# AT32F413xx register map
Vendor: Keil; Series: AT32F413; File version: 1.0
CPU: CM4 r0p1, little endian, no MPU, FPU, 4 interrupt priority bits
Registers are 32-bit, read-write, reset 0x0 unless marked. A register's access mark holds for its fields unless they carry their own. Offsets are from the block's base; [hi:lo] are bit positions; {n}, {i} and the like mark numbered series.

## PWR — Power control
Base 0x40007000
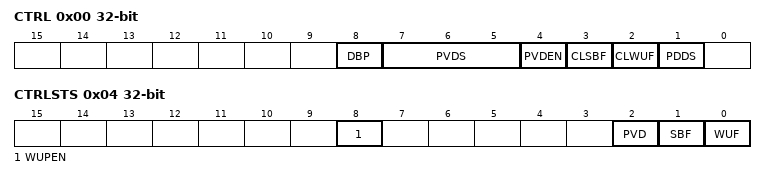
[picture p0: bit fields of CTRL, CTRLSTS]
0x00 CTRL — Power control register (PWR_CTRL)
  [8] DBP — Disable Backup Domain write protection
  [7:5] PVDS — PVD Level Selection
  [4] PVDEN — Power Voltage Detector Enable
  [3] CLSBF — Clear STANDBY Flag
  [2] CLWUF — Clear Wake-up Flag
  [1] PDDS — Power Down Deep Sleep
0x04 CTRLSTS — Power control register (PWR_CTRLST)
  [8] WUPEN — Enable WKUP pin
  [2] PVD ro — PVD Output
  [1] SBF ro — STANDBY Flag
  [0] WUF ro — Wake-Up Flag

## GPIOA — General purpose I/O
Base 0x40010800
Same registers: GPIOB 0x40010C00, GPIOC 0x40011000, GPIOD 0x40011400, GPIOF 0x40011C00
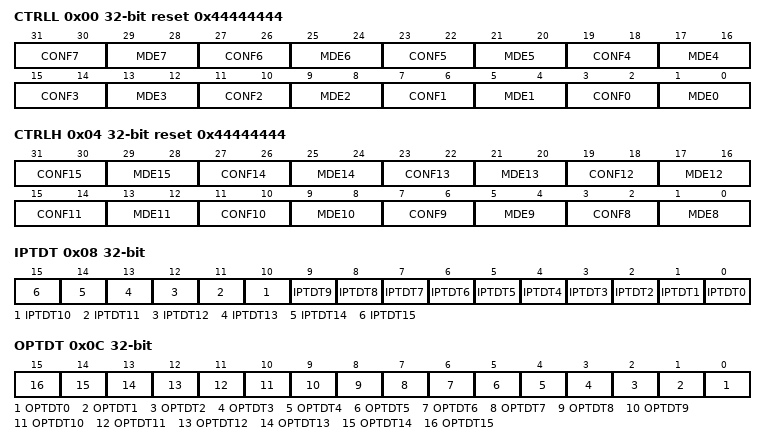
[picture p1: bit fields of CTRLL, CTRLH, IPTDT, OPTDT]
0x00 CTRLL reset 0x44444444 — Port configuration register low (GPIOn_CTRLL)
  [31:30] CONF7 — Port n.7 configuration bits
  [29:28] MDE7 — Port n.7 mode bits
  [27:26] CONF6 — Port n.6 configuration bits
  [25:24] MDE6 — Port n.6 mode bits
  [23:22] CONF5 — Port n.5 configuration bits
  [21:20] MDE5 — Port n.5 mode bits
  [19:18] CONF4 — Port n.4 configuration bits
  [17:16] MDE4 — Port n.4 mode bits
  [15:14] CONF3 — Port n.3 configuration bits
  [13:12] MDE3 — Port n.3 mode bits
  [11:10] CONF2 — Port n.2 configuration bits
  [9:8] MDE2 — Port n.2 mode bits
  [7:6] CONF1 — Port n.1 configuration bits
  [5:4] MDE1 — Port n.1 mode bits
  [3:2] CONF0 — Port n.0 configuration bits
  [1:0] MDE0 — Port n.0 mode bits
0x04 CTRLH reset 0x44444444 — Port configuration register high (GPIOn_CTRLH)
  [31:30] CONF15 — Port n.15 configuration bits
  [29:28] MDE15 — Port n.15 mode bits
  [27:26] CONF14 — Port n.14 configuration bits
  [25:24] MDE14 — Port n.14 mode bits
  [23:22] CONF13 — Port n.13 configuration bits
  [21:20] MDE13 — Port n.13 mode bits
  [19:18] CONF12 — Port n.12 configuration bits
  [17:16] MDE12 — Port n.12 mode bits
  [15:14] CONF11 — Port n.11 configuration bits
  [13:12] MDE11 — Port n.11 mode bits
  [11:10] CONF10 — Port n.10 configuration bits
  [9:8] MDE10 — Port n.10 mode bits
  [7:6] CONF9 — Port n.9 configuration bits
  [5:4] MDE9 — Port n.9 mode bits
  [3:2] CONF8 — Port n.8 configuration bits
  [1:0] MDE8 — Port n.8 mode bits
0x08 IPTDT ro — Port input data register (GPIOn_IPTDT)
  [n] IPTDT{n} (n=0..15) — Port input data
0x0C OPTDT — Port output data register (GPIOn_OPTDT)
  [n] OPTDT{n} (n=0..15) — Port output data
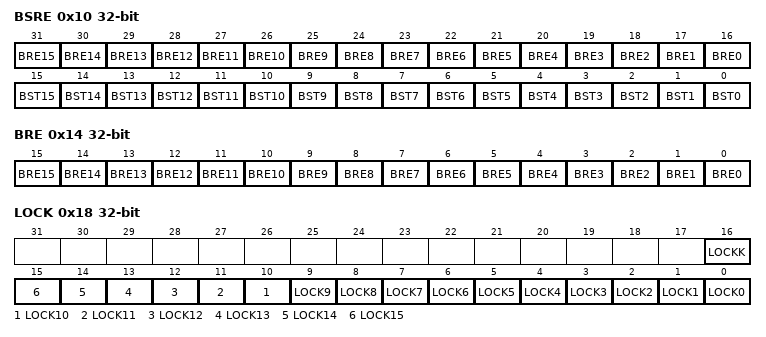
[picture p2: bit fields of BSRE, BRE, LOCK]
0x10 BSRE — Port bit set/reset register (GPIOn_BSRE)
  [n+16] BRE{n} (n=0..15) — Reset bit {n}
  [n] BST{n} (n=3..15) — Set bit {n}
  [2] BST2 — Set bit 1
  [1] BST1 — Set bit 1
  [0] BST0 — Set bit 0
0x14 BRE — Port bit reset register (GPIOn_BRE)
  [n] BRE{n} (n=3..15) — Reset bit {n}
  [2] BRE2 — Reset bit 1
  [1] BRE1 — Reset bit 1
  [0] BRE0 — Reset bit 0
0x18 LOCK — Port configuration lock register
  [16] LOCKK — Lock key
  [n] LOCK{n} (n=0..15) — Port Lock bit {n}

## AFIO — Alternate function I/O
Base 0x40010000
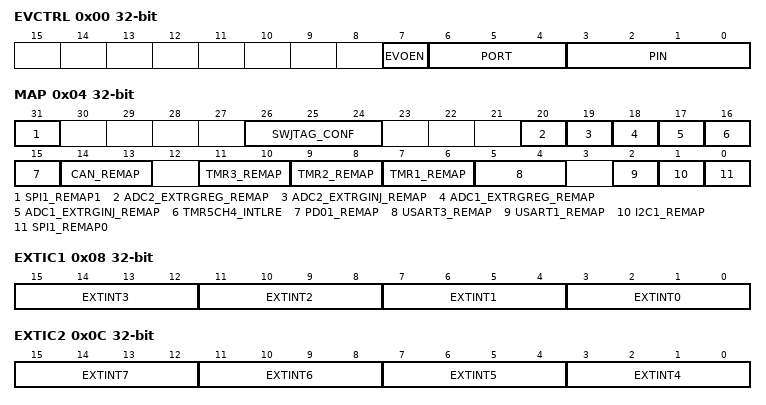
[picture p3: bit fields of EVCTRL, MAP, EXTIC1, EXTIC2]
0x00 EVCTRL — Event Control Register (AFIO_EVCTRL)
  [7] EVOEN — Event Output Enable
  [6:4] PORT — Port selection
  [3:0] PIN — Pin selection
0x04 MAP — AF remap and debug I/O configuration register (AFIO_MAP)
  [31] SPI1_REMAP1 — SPI1 remapping bit1
  [26:24] SWJTAG_CONF — Serial wire JTAG configuration
  [20] ADC2_EXTRGREG_REMAP — ADC 2 external trigger regular conversion remapping
  [19] ADC2_EXTRGINJ_REMAP — ADC 2 external trigger injected conversion remapping
  [18] ADC1_EXTRGREG_REMAP — ADC 1 external trigger regular conversion remapping
  [17] ADC1_EXTRGINJ_REMAP — ADC 1 External trigger injected conversion remapping
  [16] TMR5CH4_INTLRE — Set and cleared by software
  [15] PD01_REMAP — Port D0/Port D1 mapping on OSCIN/OSCOUT
  [14:13] CAN_REMAP — CAN1 remapping
  [11:10] TMR3_REMAP — TIM3 remapping
  [9:8] TMR2_REMAP — TIM2 remapping
  [7:6] TMR1_REMAP — TIM1 remapping
  [5:4] USART3_REMAP — USART3 remapping
  [2] USART1_REMAP — USART1 remapping
  [1] I2C1_REMAP — I2C1 remapping
  [0] SPI1_REMAP0 — SPI1 remapping bit0
0x08 EXTIC1 — External interrupt configuration register 1 (AFIO_EXTIC1)
  [4n+3:4n] EXTINT{n} (n=0..3) — EXTI{n} configuration
0x0C EXTIC2 — External interrupt configuration register 2 (AFIO_EXTIC2)
  [4n-13:4n-16] EXTINT{n} (n=4..7) — EXTI{n} configuration
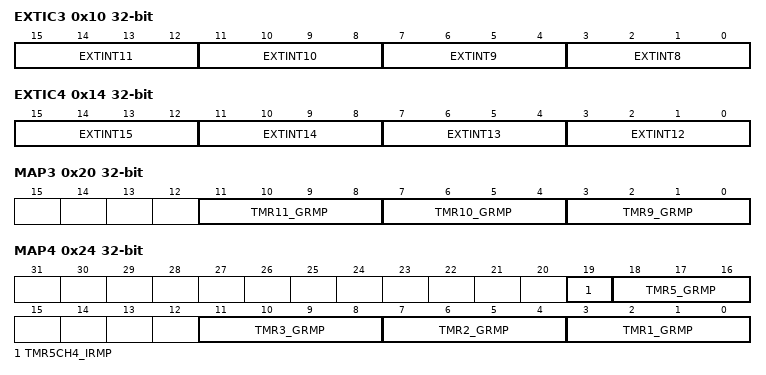
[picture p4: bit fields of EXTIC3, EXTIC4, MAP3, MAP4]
0x10 EXTIC3 — External interrupt configuration register 3 (AFIO_EXTIC3)
  [4n-29:4n-32] EXTINT{n} (n=8..11) — EXTI{n} configuration
0x14 EXTIC4 — External interrupt configuration register 4 (AFIO_EXTIC4)
  [4n-45:4n-48] EXTINT{n} (n=12..15) — EXTI{n} configuration
0x1C MAP2 — AF remap and debug I/O configuration register
  [21] EXT_SPIF_EN — Enable ExtSPIFlash
0x20 MAP3 — AF remap and debug I/O configuration register
  [11:8] TMR11_GRMP — TIM11 remapping
  [7:4] TMR10_GRMP — TIM10 remapping
  [3:0] TMR9_GRMP — TIM9 remapping
0x24 MAP4 — AF remap and debug I/O configuration register
  [19] TMR5CH4_IRMP — TMR5 channel4 internal remap
  [18:16] TMR5_GRMP — TIM5 remapping
  [11:8] TMR3_GRMP — TIM3 remapping
  [7:4] TMR2_GRMP — TIM2 remapping
  [3:0] TMR1_GRMP — TIM1 remapping
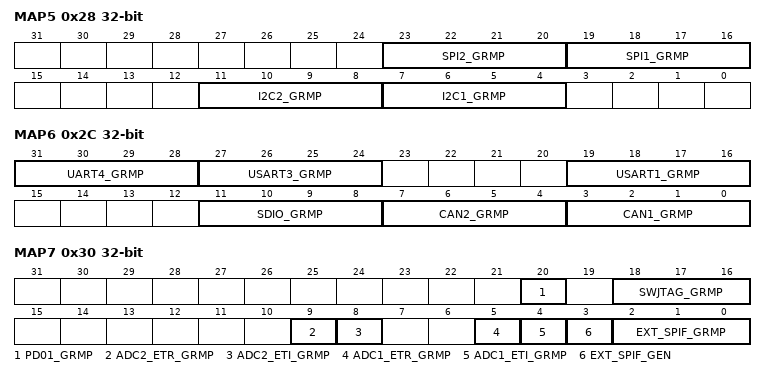
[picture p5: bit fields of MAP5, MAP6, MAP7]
0x28 MAP5 — AF remap and debug I/O configuration register
  [23:20] SPI2_GRMP — SPI2 remapping
  [19:16] SPI1_GRMP — SPI1 remapping
  [11:8] I2C2_GRMP — I2C2 remapping
  [7:4] I2C1_GRMP — I2C1 remapping
0x2C MAP6 — AF remap and debug I/O configuration register
  [31:28] UART4_GRMP — UART4 remapping
  [27:24] USART3_GRMP — USART3 remapping
  [19:16] USART1_GRMP — USART1 remapping
  [11:8] SDIO_GRMP — SDIO remapping
  [7:4] CAN2_GRMP — CAN2 remapping
  [3:0] CAN1_GRMP — CAN1 remapping
0x30 MAP7 — AF remap and debug I/O configuration register
  [20] PD01_GRMP — PortD0/PortD1 mappingon OSC_IN/OSC_OUT
  [18:16] SWJTAG_GRMP — Serial wire JTAG remapping
  [9] ADC2_ETR_GRMP — ADC2 external trigger regular conversion remapping
  [8] ADC2_ETI_GRMP — ADC2 external trigger injected conversion remapping
  [5] ADC1_ETR_GRMP — ADC1 external trigger regular conversion remapping
  [4] ADC1_ETI_GRMP — ADC1 External trigger injected conversion remapping
  [3] EXT_SPIF_GEN — External SPI Flash enable
  [2:0] EXT_SPIF_GRMP — External SPI Flash remapping

## Notices in the file
Copyright (C) 2012-2014 ARM Limited. All rights reserved.
Purpose: System Viewer Description (SVD) Example (Schema Version 1.1)
This is a description of a none-existent and incomplete device
for demonstration purposes only.
Redistribution and use in source and binary forms, with or without
modification, are permitted provided that the following conditions are met:
- Redistributions of source code must retain the above copyright
notice, this list of conditions and the following disclaimer.
- Redistributions in binary form must reproduce the above copyright
notice, this list of conditions and the following disclaimer in the
documentation and/or other materials provided with the distribution.
- Neither the name of ARM nor the names of its contributors may be used
to endorse or promote products derived from this software without
specific prior written permission.
THIS SOFTWARE IS PROVIDED BY THE COPYRIGHT HOLDERS AND CONTRIBUTORS "AS IS"
AND ANY EXPRESS OR IMPLIED WARRANTIES, INCLUDING, BUT NOT LIMITED TO, THE
IMPLIED WARRANTIES OF MERCHANTABILITY AND FITNESS FOR A PARTICULAR PURPOSE
ARE DISCLAIMED. IN NO EVENT SHALL COPYRIGHT HOLDERS AND CONTRIBUTORS BE
LIABLE FOR ANY DIRECT, INDIRECT, INCIDENTAL, SPECIAL, EXEMPLARY, OR
CONSEQUENTIAL DAMAGES (INCLUDING, BUT NOT LIMITED TO, PROCUREMENT OF
SUBSTITUTE GOODS OR SERVICES; LOSS OF USE, DATA, OR PROFITS; OR BUSINESS
INTERRUPTION) HOWEVER CAUSED AND ON ANY THEORY OF LIABILITY, WHETHER IN
CONTRACT, STRICT LIABILITY, OR TORT (INCLUDING NEGLIGENCE OR OTHERWISE)
ARISING IN ANY WAY OUT OF THE USE OF THIS SOFTWARE, EVEN IF ADVISED OF THE
POSSIBILITY OF SUCH DAMAGE.
